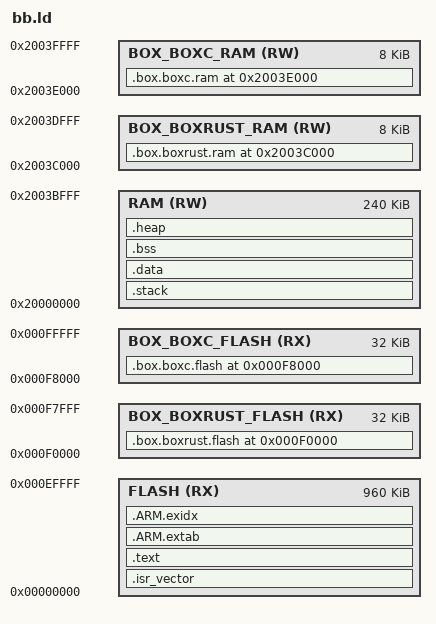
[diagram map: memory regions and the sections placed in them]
/***** AUTOGENERATED *****/

ENTRY(__box_reset_handler)

/* overridable constants */
__stack_min      = DEFINED(__stack_min) ? __stack_min : 0x00000800;
__heap_min       = DEFINED(__heap_min) ? __heap_min : 0x00000800;

/* box boxc jumptable */
__box_boxc_jumptable = __box_boxc_flash_start;

/* box boxrust jumptable */
__box_boxrust_jumptable = __box_boxrust_flash_start;

/* call region */
__box_callregion = 0x00100000;
__box_return = __box_callregion;

/* box calls */
__box_boxc_postinit      = __box_callregion + 4*(2 + 2*0 + 0) + 2*1 + 1;
__box_import_boxc_add2   = __box_callregion + 4*(2 + 2*1 + 0) + 2*1 + 1;
__box_import_boxc_fib    = __box_callregion + 4*(2 + 2*2 + 0) + 2*1 + 1;
__box_import_boxc_fib_alloc = __box_callregion + 4*(2 + 2*3 + 0) + 2*0 + 1;
__box_import_boxc_fib_next = __box_callregion + 4*(2 + 2*4 + 0) + 2*1 + 1;
__box_import_boxc_hello  = __box_callregion + 4*(2 + 2*5 + 0) + 2*1 + 1;
__box_import_boxc_qsort  = __box_callregion + 4*(2 + 2*6 + 0) + 2*1 + 1;
__box_import_boxc_qsort_alloc = __box_callregion + 4*(2 + 2*7 + 0) + 2*0 + 1;
__box_import_boxc_qsort_partition = __box_callregion + 4*(2 + 2*8 + 0) + 2*1 + 1;
__box_boxrust_postinit   = __box_callregion + 4*(2 + 2*0 + 1) + 2*1 + 1;
__box_import_boxrust_add2 = __box_callregion + 4*(2 + 2*1 + 1) + 2*1 + 1;
__box_import_boxrust_fib = __box_callregion + 4*(2 + 2*2 + 1) + 2*1 + 1;
__box_import_boxrust_fib_alloc = __box_callregion + 4*(2 + 2*3 + 1) + 2*0 + 1;
__box_import_boxrust_fib_next = __box_callregion + 4*(2 + 2*4 + 1) + 2*1 + 1;
__box_import_boxrust_hello = __box_callregion + 4*(2 + 2*5 + 1) + 2*1 + 1;
__box_import_boxrust_qsort = __box_callregion + 4*(2 + 2*6 + 1) + 2*1 + 1;
__box_import_boxrust_qsort_alloc = __box_callregion + 4*(2 + 2*7 + 1) + 2*0 + 1;
__box_import_boxrust_qsort_partition = __box_callregion + 4*(2 + 2*8 + 1) + 2*1 + 1;

MEMORY {
    FLASH            (RX ) : ORIGIN = 0x00000000, LENGTH = 0x000f0000
    BOX_BOXRUST_FLASH (RX ) : ORIGIN = 0x000f0000, LENGTH = 0x00008000
    BOX_BOXC_FLASH   (RX ) : ORIGIN = 0x000f8000, LENGTH = 0x00008000
    RAM              (RW ) : ORIGIN = 0x20000000, LENGTH = 0x0003c000
    BOX_BOXRUST_RAM  (RW ) : ORIGIN = 0x2003c000, LENGTH = 0x00002000
    BOX_BOXC_RAM     (RW ) : ORIGIN = 0x2003e000, LENGTH = 0x00002000
}

SECTIONS {
    /* FLASH sections */
    . = ORIGIN(FLASH);
    . = ALIGN(4);
    __isr_vector_start = .;
    .isr_vector . : {
        KEEP(*(.isr_vector))
        . = __isr_vector_start + 0x400;
    } > FLASH
    . = ALIGN(4);
    __isr_vector_end = .;

    . = ALIGN(4);
    __text_start = .;
    .text . : {
        *(.text*)
        *(.rodata*)
        *(.glue_7*)
        *(.glue_7t*)
        *(.eh_frame*)

        KEEP(*(SORT_NONE(.init)))
        KEEP(*(SORT_NONE(.init*)))
        KEEP(*(SORT_NONE(.fini)))
        KEEP(*(SORT_NONE(.fini*)))

        . = ALIGN(4);
        PROVIDE_HIDDEN(__preinit_array_start = .);
        KEEP(*(SORT(.preinit_array)))
        PROVIDE_HIDDEN(__preinit_array_end = .);

        . = ALIGN(4);
        PROVIDE_HIDDEN(__init_array_start = .);
        KEEP(*(SORT(.init_array.*)))
        PROVIDE_HIDDEN(__init_array_end = .);

        . = ALIGN(4);
        PROVIDE_HIDDEN(__fini_array_start = .);
        KEEP(*(SORT(.fini_array.*)))
        PROVIDE_HIDDEN(__fini_array_end = .);

        KEEP(*crtbegin.o(.ctors))
        KEEP(*crtbegin?.o(.ctors))
        KEEP(*(EXCLUDE_FILE(*crtend?.o *crtend.o) .ctors))
        KEEP(*(SORT(.ctors.*)))

        KEEP(*crtbegin.o(.dtors))
        KEEP(*crtbegin?.o(.dtors))
        KEEP(*(EXCLUDE_FILE(*crtend?.o *crtend.o) .dtors))
        KEEP(*(SORT(.dtors.*)))
    } > FLASH
    . = ALIGN(4);
    __text_end = .;

    __extab_start = .;
    .ARM.extab : {
        *(.ARM.extab* .gnu.linkonce.armextab.*)
    } > FLASH
    __extab_end = .;

    __exidx_start = .;
    .ARM.exidx : {
        *(.ARM.exidx* .gnu.linkonce.armexidx.*)
    } > FLASH
    __exidx_end = .;

    . = ALIGN(4);
    __data_init_start = .;

    /* BOX_BOXRUST_FLASH sections */
    . = ORIGIN(BOX_BOXRUST_FLASH);
    __box_boxrust_flash_start = .;
    .box.boxrust.flash . : {
        KEEP(*(.box.boxrust.flash*))
    } > BOX_BOXRUST_FLASH
    . = ORIGIN(BOX_BOXRUST_FLASH) + LENGTH(BOX_BOXRUST_FLASH);
    __box_boxrust_flash_end = .;

    /* BOX_BOXC_FLASH sections */
    . = ORIGIN(BOX_BOXC_FLASH);
    __box_boxc_flash_start = .;
    .box.boxc.flash . : {
        KEEP(*(.box.boxc.flash*))
    } > BOX_BOXC_FLASH
    . = ORIGIN(BOX_BOXC_FLASH) + LENGTH(BOX_BOXC_FLASH);
    __box_boxc_flash_end = .;

    /* RAM sections */
    . = ORIGIN(RAM);
    . = ALIGN(4);
    __stack_start = .;
    .stack . (NOLOAD) : {
        . = .;
    } > RAM
    . += __stack_min;
    . = ALIGN(4);
    __stack_end = .;

    . = ALIGN(4);
    __data_start = .;
    .data . : AT(__data_init_start) {
        *(.data*)
    } > RAM
    . = ALIGN(4);
    __data_end = .;

    __data_init_end = LOADADDR(.data) + SIZEOF(.data);
    ASSERT(__data_init_end <= ORIGIN(FLASH) + LENGTH(FLASH),
        "Not enough memory in FLASH for data init")

    . = ALIGN(4);
    __bss_start = .;
    __bss_start__ = .;
    .bss . (NOLOAD) : {
        *(.bss*)
        *(COMMON)
    } > RAM
    . = ALIGN(4);
    __bss_end = .;
    __bss_end__ = .;

    . = ALIGN(4);
    __heap_start = .;
    __end__ = .;
    PROVIDE(end = .);
    .heap . (NOLOAD) : {
        . = .;
    } > RAM
    . = ORIGIN(RAM) + LENGTH(RAM);
    . = ALIGN(4);
    __heap_end = .;
    __heap_limit = .;

    ASSERT(__heap_end - __heap_start > __heap_min,
        "Not enough memory in RAM for heap")

    /* BOX_BOXRUST_RAM sections */
    . = ORIGIN(BOX_BOXRUST_RAM);
    __box_boxrust_ram_start = .;
    .box.boxrust.ram . (NOLOAD): {
        KEEP(*(.box.boxrust.ram*))
    } > BOX_BOXRUST_RAM
    . = ORIGIN(BOX_BOXRUST_RAM) + LENGTH(BOX_BOXRUST_RAM);
    __box_boxrust_ram_end = .;

    /* BOX_BOXC_RAM sections */
    . = ORIGIN(BOX_BOXC_RAM);
    __box_boxc_ram_start = .;
    .box.boxc.ram . (NOLOAD): {
        KEEP(*(.box.boxc.ram*))
    } > BOX_BOXC_RAM
    . = ORIGIN(BOX_BOXC_RAM) + LENGTH(BOX_BOXC_RAM);
    __box_boxc_ram_end = .;
}

